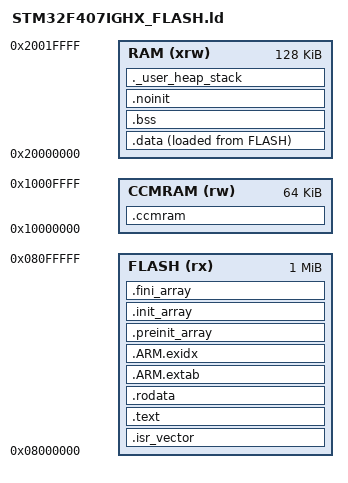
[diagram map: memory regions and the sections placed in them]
/* STM32F407IG: match the original Keil scatter file (no bootloader offset).
 * CCM is opt-in; DMA buffers remain in the 128 KiB SRAM at 0x20000000.
 */
ENTRY(Reset_Handler)

_estack = ORIGIN(RAM) + LENGTH(RAM);
_Min_Heap_Size = 0x2000;
_Min_Stack_Size = 0x2000;

MEMORY
{
    FLASH (rx)  : ORIGIN = 0x08000000, LENGTH = 1024K
    RAM (xrw)   : ORIGIN = 0x20000000, LENGTH = 128K
    CCMRAM (rw) : ORIGIN = 0x10000000, LENGTH = 64K
}

SECTIONS
{
    .isr_vector :
    {
        . = ALIGN(4);
        KEEP(*(.isr_vector))
        . = ALIGN(4);
    } > FLASH

    .text :
    {
        . = ALIGN(4);
        *(.text .text.*)
        *(.glue_7 .glue_7t)
        KEEP(*(.init))
        KEEP(*(.fini))
        . = ALIGN(4);
        _etext = .;
    } > FLASH

    .rodata :
    {
        . = ALIGN(4);
        *(.rodata .rodata.*)
        . = ALIGN(4);
    } > FLASH

    .ARM.extab : { *(.ARM.extab* .gnu.linkonce.armextab.*) } > FLASH
    .ARM.exidx :
    {
        __exidx_start = .;
        *(.ARM.exidx* .gnu.linkonce.armexidx.*)
        __exidx_end = .;
    } > FLASH

    .preinit_array (READONLY) :
    {
        PROVIDE_HIDDEN(__preinit_array_start = .);
        KEEP(*(.preinit_array*))
        PROVIDE_HIDDEN(__preinit_array_end = .);
    } > FLASH
    .init_array (READONLY) :
    {
        PROVIDE_HIDDEN(__init_array_start = .);
        KEEP(*(SORT(.init_array.*)))
        KEEP(*(.init_array*))
        PROVIDE_HIDDEN(__init_array_end = .);
    } > FLASH
    .fini_array (READONLY) :
    {
        PROVIDE_HIDDEN(__fini_array_start = .);
        KEEP(*(SORT(.fini_array.*)))
        KEEP(*(.fini_array*))
        PROVIDE_HIDDEN(__fini_array_end = .);
    } > FLASH

    _sidata = LOADADDR(.data);
    .data :
    {
        . = ALIGN(4);
        _sdata = .;
        *(.data .data.*)
        *(.RamFunc .RamFunc.*)
        . = ALIGN(4);
        _edata = .;
    } > RAM AT> FLASH

    .bss (NOLOAD) :
    {
        . = ALIGN(4);
        _sbss = .;
        __bss_start__ = .;
        *(.bss .bss.*)
        *(COMMON)
        . = ALIGN(4);
        _ebss = .;
        __bss_end__ = .;
    } > RAM

    .noinit (NOLOAD) :
    {
        . = ALIGN(8);
        *(.noinit .noinit.*)
        . = ALIGN(8);
    } > RAM

    ._user_heap_stack (NOLOAD) :
    {
        . = ALIGN(8);
        PROVIDE(end = .);
        PROVIDE(_end = .);
        __HeapBase = .;
        . += _Min_Heap_Size;
        __HeapLimit = .;
        . += _Min_Stack_Size;
        . = ALIGN(8);
    } > RAM
    __StackLimit = _estack - _Min_Stack_Size;
    ASSERT(__HeapLimit <= __StackLimit, "SRAM heap overlaps the main/ISR stack")

    /* Explicit zero-initialized CCM section, cleared by the GCC startup. */
    .ccmram (NOLOAD) :
    {
        . = ALIGN(4);
        _sccmram = .;
        *(.ccmram .ccmram.*)
        . = ALIGN(4);
        _eccmram = .;
    } > CCMRAM

    .ARM.attributes 0 : { *(.ARM.attributes) }
}
